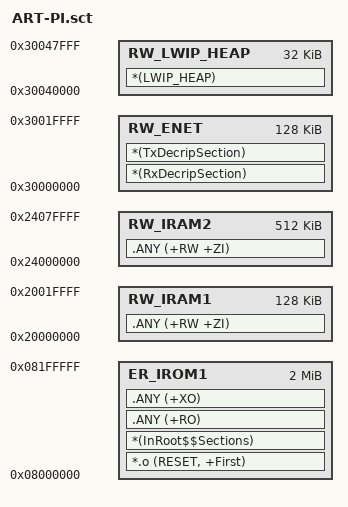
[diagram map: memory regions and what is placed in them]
; *************************************************************
; *** Scatter-Loading Description File generated by uVision ***
; *************************************************************

LR_IROM1 0x08000000 0x00200000  {    ; load region size_region
  ER_IROM1 0x08000000 0x00200000  {  ; load address = execution address
   *.o (RESET, +First)
   *(InRoot$$Sections)
   .ANY (+RO)
   .ANY (+XO)
  }
  RW_IRAM1 0x20000000 0x00020000  {  ; 128KB RW data
   .ANY (+RW +ZI)
  }
  RW_IRAM2 0x24000000 0x00080000  {   ; 512KB
   .ANY (+RW +ZI)
  }
  RW_ENET  0x30000000 0x00020000  {   ; 128KB 此处还剩大部分RAM未使用
   *(RxDecripSection)
   *(TxDecripSection)
  }
  RW_LWIP_HEAP 0x30040000 0x00008000  {   ; 32KB
   *(LWIP_HEAP)
  }
}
